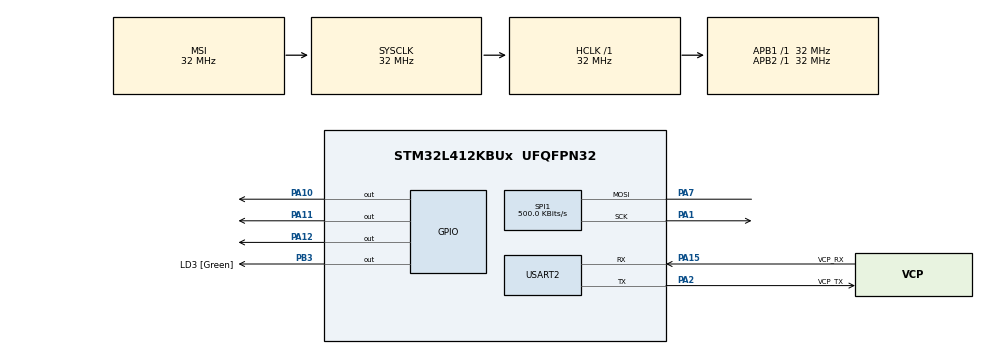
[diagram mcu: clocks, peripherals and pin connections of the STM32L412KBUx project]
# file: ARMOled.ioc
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Mcu.Family=STM32L4
Mcu.Name=STM32L412KBUx
Mcu.Package=UFQFPN32
NVIC.PriorityGroup=NVIC_PRIORITYGROUP_4
PA0-CK_IN.Mode=HSE-External-Clock-Source-for-LittleOrca
PA0-CK_IN.Signal=RCC_CK_IN
PA1.Mode=Simplex_Bidirectional_Master
PA1.Signal=SPI1_SCK
PA10.Signal=GPIO_Output
PA11.Signal=GPIO_Output
PA12.Signal=GPIO_Output
PA13\ (JTMS/SWDIO).GPIO_Label=SWDIO
PA13\ (JTMS/SWDIO).Mode=Serial_Wire
PA13\ (JTMS/SWDIO).Signal=SYS_JTMS-SWDIO
PA14\ (JTCK/SWCLK).GPIO_Label=SWCLK
PA14\ (JTCK/SWCLK).Mode=Serial_Wire
PA14\ (JTCK/SWCLK).Signal=SYS_JTCK-SWCLK
PA15\ (JTDI).GPIO_Label=VCP_RX
PA15\ (JTDI).Mode=Asynchronous
PA15\ (JTDI).Signal=USART2_RX
PA2.GPIO_Label=VCP_TX
PA2.Mode=Asynchronous
PA2.Signal=USART2_TX
PA7.Mode=Simplex_Bidirectional_Master
PA7.Signal=SPI1_MOSI
PB3\ (JTDO/TRACESWO).GPIO_Label=LD3 [Green]
PB3\ (JTDO/TRACESWO).Signal=GPIO_Output
PC14-OSC32_IN\ (PC14).Mode=LSE-External-Oscillator
PC14-OSC32_IN\ (PC14).Signal=RCC_OSC32_IN
PC15-OSC32_OUT\ (PC15).Mode=LSE-External-Oscillator
PC15-OSC32_OUT\ (PC15).Signal=RCC_OSC32_OUT
ProjectManager.HeapSize=0x200
ProjectManager.StackSize=0x400
ProjectManager.TargetToolchain=SW4STM32
RCC.ADCFreq_Value=32000000
RCC.AHBFreq_Value=32000000
RCC.APB1Freq_Value=32000000
RCC.APB1TimFreq_Value=32000000
RCC.APB2Freq_Value=32000000
RCC.APB2TimFreq_Value=32000000
RCC.CortexFreq_Value=32000000
RCC.FLatency=FLASH_LATENCY_1
RCC.HCLKFreq_Value=32000000
RCC.HSE_VALUE=8000000
RCC.HSI48_VALUE=48000000
RCC.HSICalibrationValue=16
RCC.HSI_VALUE=16000000
RCC.LSE_Drive_Capability=RCC_LSEDRIVE_LOW
RCC.MSIClockRange=RCC_MSIRANGE_10
RCC.MSI_VALUE=32000000
RCC.SYSCLKFreq_VALUE=32000000
RCC.USBFreq_Value=32000000
RCC.VCOOutputFreq_Value=256000000
SPI1.BaudRatePrescaler=SPI_BAUDRATEPRESCALER_64
SPI1.CalculateBaudRate=500.0 KBits/s
SPI1.DataSize=SPI_DATASIZE_8BIT
SPI1.Direction=SPI_DIRECTION_1LINE
SPI1.Mode=SPI_MODE_MASTER
SPI1.NSSPMode=SPI_NSS_PULSE_DISABLE
SPI1.VirtualType=VM_MASTER
USART2.VirtualMode-Asynchronous=VM_ASYNC
board=NUCLEO-L412KB

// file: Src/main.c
/* USER CODE BEGIN Header */
/**
  ******************************************************************************
  * @file           : main.c
  * @brief          : Main program body
  ******************************************************************************
  ** This notice applies to any and all portions of this file
  * that are not between comment pairs USER CODE BEGIN and
  * USER CODE END. Other portions of this file, whether
  * inserted by the user or by software development tools
  * are owned by their respective copyright owners.
  *
  * COPYRIGHT(c) 2019 STMicroelectronics
  *
  * Redistribution and use in source and binary forms, with or without modification,
  * are permitted provided that the following conditions are met:
  *   1. Redistributions of source code must retain the above copyright notice,
  *      this list of conditions and the following disclaimer.
  *   2. Redistributions in binary form must reproduce the above copyright notice,
  *      this list of conditions and the following disclaimer in the documentation
  *      and/or other materials provided with the distribution.
  *   3. Neither the name of STMicroelectronics nor the names of its contributors
  *      may be used to endorse or promote products derived from this software
  *      without specific prior written permission.
  *
  * THIS SOFTWARE IS PROVIDED BY THE COPYRIGHT HOLDERS AND CONTRIBUTORS "AS IS"
  * AND ANY EXPRESS OR IMPLIED WARRANTIES, INCLUDING, BUT NOT LIMITED TO, THE
  * IMPLIED WARRANTIES OF MERCHANTABILITY AND FITNESS FOR A PARTICULAR PURPOSE ARE
  * DISCLAIMED. IN NO EVENT SHALL THE COPYRIGHT HOLDER OR CONTRIBUTORS BE LIABLE
  * FOR ANY DIRECT, INDIRECT, INCIDENTAL, SPECIAL, EXEMPLARY, OR CONSEQUENTIAL
  * DAMAGES (INCLUDING, BUT NOT LIMITED TO, PROCUREMENT OF SUBSTITUTE GOODS OR
  * SERVICES; LOSS OF USE, DATA, OR PROFITS; OR BUSINESS INTERRUPTION) HOWEVER
  * CAUSED AND ON ANY THEORY OF LIABILITY, WHETHER IN CONTRACT, STRICT LIABILITY,
  * OR TORT (INCLUDING NEGLIGENCE OR OTHERWISE) ARISING IN ANY WAY OUT OF THE USE
  * OF THIS SOFTWARE, EVEN IF ADVISED OF THE POSSIBILITY OF SUCH DAMAGE.
  *
  ******************************************************************************
  */
/* USER CODE END Header */

#include "main.h"
#include "spi.h"
#include "usart.h"
#include "gpio.h"

/* USER CODE BEGIN Includes */
#include "ssd1306.h"

/* USER CODE END Includes */

void SystemClock_Config(void);

int main(void)
{

  /* MCU Configuration--------------------------------------------------------*/

  /* Reset of all peripherals, Initializes the Flash interface and the Systick. */
  HAL_Init();

  /* Configure the system clock */
  SystemClock_Config();

  /* Initialize all configured peripherals */
  MX_GPIO_Init();
  MX_USART2_UART_Init();
  MX_SPI1_Init();

  /* Infinite loop */
  /* USER CODE BEGIN WHILE */
  ssd1306_Init();
  ssd1306_Fill(Black);
  ssd1306_SetCursor(31, 18);
  ssd1306_WriteString("YEA", Font_11x18, White);
  ssd1306_SetCursor(75, 18);
  ssd1306_WriteString("!", Font_16x26, White);
  ssd1306_UpdateScreen();
  while (1)
  {
	  HAL_GPIO_TogglePin(GPIOB,GPIO_PIN_3);
	  HAL_Delay(500);

    /* USER CODE END WHILE */

  }
}

void SystemClock_Config(void)
{
  RCC_OscInitTypeDef RCC_OscInitStruct = {0};
  RCC_ClkInitTypeDef RCC_ClkInitStruct = {0};
  RCC_PeriphCLKInitTypeDef PeriphClkInit = {0};

  /**Configure LSE Drive Capability
  */
  HAL_PWR_EnableBkUpAccess();
  __HAL_RCC_LSEDRIVE_CONFIG(RCC_LSEDRIVE_LOW);
  /**Configure the main internal regulator output voltage
  */
  if (HAL_PWREx_ControlVoltageScaling(PWR_REGULATOR_VOLTAGE_SCALE1) != HAL_OK)
  {
    Error_Handler();
  }
  /**Initializes the CPU, AHB and APB busses clocks
  */
  RCC_OscInitStruct.OscillatorType = RCC_OSCILLATORTYPE_LSE|RCC_OSCILLATORTYPE_MSI;
  RCC_OscInitStruct.LSEState = RCC_LSE_ON;
  RCC_OscInitStruct.MSIState = RCC_MSI_ON;
  RCC_OscInitStruct.MSICalibrationValue = 0;
  RCC_OscInitStruct.MSIClockRange = RCC_MSIRANGE_10;
  RCC_OscInitStruct.PLL.PLLState = RCC_PLL_NONE;
  if (HAL_RCC_OscConfig(&RCC_OscInitStruct) != HAL_OK)
  {
    Error_Handler();
  }
  /**Initializes the CPU, AHB and APB busses clocks
  */
  RCC_ClkInitStruct.ClockType = RCC_CLOCKTYPE_HCLK|RCC_CLOCKTYPE_SYSCLK
                              |RCC_CLOCKTYPE_PCLK1|RCC_CLOCKTYPE_PCLK2;
  RCC_ClkInitStruct.SYSCLKSource = RCC_SYSCLKSOURCE_MSI;
  RCC_ClkInitStruct.AHBCLKDivider = RCC_SYSCLK_DIV1;
  RCC_ClkInitStruct.APB1CLKDivider = RCC_HCLK_DIV1;
  RCC_ClkInitStruct.APB2CLKDivider = RCC_HCLK_DIV1;

  if (HAL_RCC_ClockConfig(&RCC_ClkInitStruct, FLASH_LATENCY_1) != HAL_OK)
  {
    Error_Handler();
  }
  PeriphClkInit.PeriphClockSelection = RCC_PERIPHCLK_USART2;
  PeriphClkInit.Usart2ClockSelection = RCC_USART2CLKSOURCE_PCLK1;
  if (HAL_RCCEx_PeriphCLKConfig(&PeriphClkInit) != HAL_OK)
  {
    Error_Handler();
  }
  /**Enable MSI Auto calibration
  */
  HAL_RCCEx_EnableMSIPLLMode();
}

void Error_Handler(void)
{
}

/************************ (C) COPYRIGHT STMicroelectronics *****END OF FILE****/
